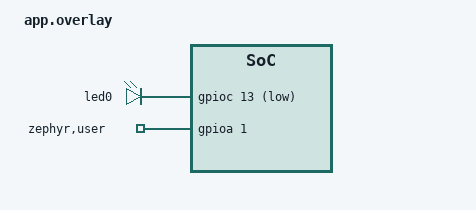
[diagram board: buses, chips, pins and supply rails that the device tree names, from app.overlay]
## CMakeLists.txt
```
# SPDX-License-Identifier: Apache-2.0

cmake_minimum_required(VERSION 3.20.0)
find_package(Zephyr REQUIRED HINTS $ENV{ZEPHYR_BASE})
project(001SSD1306_Demo)
file(GLOB app_sources src/*.c)
target_sources(app PRIVATE ${app_sources})
target_include_directories(app PRIVATE inc)
```

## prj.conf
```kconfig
# GPIO
CONFIG_GPIO=y # Ativar o controle dos pinos input e output

# Logging
CONFIG_LOG=y # Log de debug (UART 1)

# 3: info, 0: nada
CONFIG_LOG_DEFAULT_LEVEL=3 

# Para printar float
CONFIG_CBPRINTF_FP_SUPPORT=y
```

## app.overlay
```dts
// / {
// 	leds {
// 		compatible = "gpio-leds";
// 		userled: led_1 {
// 			gpios = <&gpioc 13 GPIO_ACTIVE_LOW>;
// 			label = "LED 1";
// 			status = "okay";
// 		};
// 	};

// 	aliases {
// 		led1 = &userled;
// 	};

// };

// &usart1 {
// 	status = "okay";
// 	current-speed = <115200>;
// 	pinctrl-0 = <&usart1_tx_pa9 &usart1_rx_pa10>;
// 	pinctrl-names = "default";
// };

// &i2c1 {
// 	status = "okay";
// 	clock-frequency = <I2C_BITRATE_STANDARD>;
// 	pinctrl-0 = <&i2c1_scl_pb6 &i2c1_sda_pb7>;
// 	pinctrl-names = "default";

// 	mpu6050: mpu6050@68 {
// 		compatible = "invensense,mpu6050";
// 		reg = <0x68>;
// 		status = "okay";
// 		int-gpios = <&gpiob 5 GPIO_ACTIVE_HIGH>;
// 	};
// ssd1306: ssd1306@3c {
// 	compatible = "solomon,ssd1306fb";
// 	reg = <0x3c>;
// 	label = "SSD1306";
// 	width = <128>;
// 	height = <64>;
// 	segment-offset = <0>;
// 	page-offset = <0>;
// 	display-offset = <0>;
// 	multiplex-ratio = <63>;
// 	segment-remap;
// 	com-invdir;
// 	prechargep = <0x22>;
// 	reset-gpios = <&gpioa 1 GPIO_ACTIVE_LOW>;
// };
// };
/ {
	// LED da BLuepill
	leds {
		compatible = "gpio-leds";
		led0: led {
			gpios = <&gpioc 13 GPIO_ACTIVE_LOW>;
		};
	};
	
	zephyr,user {
		gpios = <&gpioa 1 GPIO_ACTIVE_HIGH>;// Onewire
	};
	
	aliases {
	};
};
```

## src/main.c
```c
#include "ds18b20.h"
#include <float.h>
#include <zephyr/drivers/gpio.h>
#include <zephyr/kernel.h>
#include <zephyr/logging/log.h>
#include <zephyr/logging/log_ctrl.h>
#include <zephyr/timing/timing.h>

LOG_MODULE_REGISTER();

int main() {
  float temperatura;
  log_panic();
  while (1) {
    k_msleep(5);
    temperatura = ds18b20_get_temperature();

    if (temperatura == FLT_MIN) {
      LOG_ERR("Erro ao ler a temperatura do sensor");
    }
  }
}
```

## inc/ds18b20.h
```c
/**
 * @brief Tenta obter a leitura de temperatura do sensor. A temperatura é lida
 * em graus Celsius e tem resolução de 0.0625.
 *
 * @return Caso consiga obter a temperatura, retorna a temperatura lida. Caso
 * não consiga obter a leitura do sensor, retorna FLT_MIN (da biblioteca
 * float.h).
 */
extern float ds18b20_get_temperature(void);
```

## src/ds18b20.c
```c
#include "ds18b20.h"
#include <float.h>
#include <zephyr/drivers/gpio.h>
#include <zephyr/kernel.h>
#include <zephyr/logging/log.h>

LOG_MODULE_REGISTER(Temperatura);

static const struct gpio_dt_spec *const w1 =
    &(const struct gpio_dt_spec)GPIO_DT_SPEC_GET(DT_PATH(zephyr_user), gpios);

/**
 * @brief Faz que o processador aguarde por tempo_us microssegundos.
 */
static void delay_us(uint32_t tempo_us) { k_busy_wait(tempo_us); }

/**
 * @brief Envia um sinal de presença para o sensor e verifica se há um sinal de
 * resposta vindo do sensor.
 *
 * @return 0, caso seja detectada uma resposta do sensor. -1, caso contrário.
 */
static uint8_t ds18b20_start() {
  if (!device_is_ready(w1->port)) {
    LOG_ERR("O dispositivo não está pronto para ser usado.");
    return -1;
  }
  uint8_t ret;

  gpio_pin_configure_dt(w1, GPIO_OUTPUT);

  gpio_pin_set_dt(w1, 0);
  delay_us(480);

  gpio_pin_configure_dt(w1, GPIO_INPUT);
  delay_us(80);

  if (!gpio_pin_get_dt(w1)) {
    ret = 0;
  } else {
    LOG_ERR("Não houve resposta de presença do sensor.");
    ret = -1;
  }

  delay_us(400);
  return ret;
}

/**
 * @brief Transmite um byte pelo barramento OneWire para o sensor.
 *
 * @param data Byte a ser transmitido para o sensor.
 */
static void ds18b20_write(uint8_t data) {
  gpio_pin_configure_dt(w1, GPIO_OUTPUT);

  for (int i = 0; i < 8; i++) {
    if ((data & (1 << i)) != 0) // if the bit is high
    {
      // write 1
      gpio_pin_configure_dt(w1, GPIO_OUTPUT);
      gpio_pin_set_dt(w1, 0);
      delay_us(1); // wait for 1 us

      gpio_pin_configure_dt(w1, GPIO_INPUT);
      delay_us(60); // wait for 60 us
    }

    else // if the bit is low
    {
      // write 0
      gpio_pin_configure_dt(w1, GPIO_OUTPUT);
      gpio_pin_set_dt(w1, 0);
      delay_us(60); // wait for 60 us

      gpio_pin_configure_dt(w1, GPIO_INPUT);
    }
  }
}

/**
 * @brief Lê um byte enviado pelo sensor através do barramento OneWire. \n
 * Note que cabe ao usuário dessa função garantir que há um byte relevante a ser
 * lido no barramento OneWire.
 *
 * @return Byte lido.
 */
static uint8_t ds18b20_read() {
  uint8_t value = 0;
  gpio_pin_configure_dt(w1, GPIO_INPUT);

  for (int i = 0; i < 8; i++) {
    gpio_pin_configure_dt(w1, GPIO_OUTPUT);
    gpio_pin_set_dt(w1, 0);
    delay_us(2); // wait for 2 us
    gpio_pin_configure_dt(w1, GPIO_INPUT);
    if (gpio_pin_get_dt(w1)) // if the pin is HIGH
    {
      value |= 1 << i; // read = 1
    }
    delay_us(60); // wait for 60 us
  }
  return value;
}

float ds18b20_get_temperature() {
  if (ds18b20_start())
    return FLT_MIN;
  ds18b20_write(0xCC); // skip ROM
  ds18b20_write(0x44); // convert t

  if (ds18b20_start())
    return FLT_MIN;
  ds18b20_write(0xCC); // skip ROM
  ds18b20_write(0xBE); // Read Scratch-Pad

  float temperature = ds18b20_read();
  temperature += ds18b20_read() << 8;
  temperature /= 16.0;

  return temperature;
}
```
